VERSION ""

NS_ :

BS_:

BU_: XXX BCM CEM CVM DIM ECM FSM PSCM SAS SRS TCM

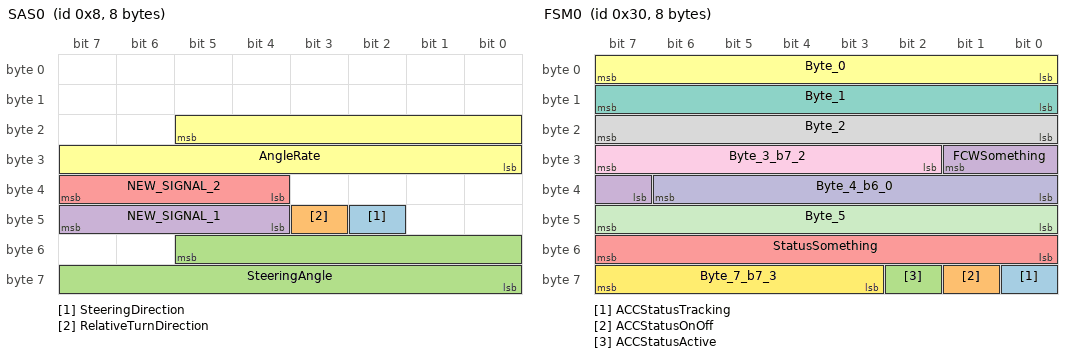
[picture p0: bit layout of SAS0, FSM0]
BO_ 8 SAS0: 8 SAS
 SG_ SteeringDirection : 42|1@0+ (1,0) [0|1] "" XXX
 SG_ RelativeTurnDirection : 43|1@0+ (1,0) [0|1] "" XXX
 SG_ SteeringAngle : 53|14@0+ (0.04395,0) [0|65535] "degrees" XXX
 SG_ NEW_SIGNAL_1 : 47|4@0+ (1,0) [0|15] "" XXX
 SG_ NEW_SIGNAL_2 : 39|4@0+ (1,0) [0|15] "" XXX
 SG_ AngleRate : 21|14@0+ (0.075,0) [0|1500] "deg/S" XXX

BO_ 16 CCButtons: 8 CEM
 SG_ byte0 : 7|8@0+ (1,0) [0|255] "" XXX
 SG_ byte1 : 15|8@0+ (1,0) [0|255] "" XXX
 SG_ byte2 : 23|8@0+ (1,0) [0|255] "" XXX
 SG_ byte3 : 31|8@0+ (1,0) [0|255] "" XXX
 SG_ byte4 : 39|8@0+ (1,0) [0|255] "" XXX
 SG_ byte6 : 55|5@0+ (1,0) [0|31] "" XXX
 SG_ B7b0 : 56|1@0+ (1,0) [0|1] "" XXX
 SG_ B7b1 : 57|1@0+ (1,0) [0|1] "" XXX
 SG_ B7b6 : 62|1@0+ (1,0) [0|1] "" XXX
 SG_ ACCOnOffBtn : 58|1@0+ (1,0) [0|1] "" XXX
 SG_ ACCSetBtn : 63|1@0+ (1,0) [0|1] "" XXX
 SG_ ACCStopBtn : 60|1@0+ (1,0) [0|1] "" XXX
 SG_ ACCResumeBtn : 61|1@0+ (1,0) [0|1] "" XXX
 SG_ ACCMinusBtn : 48|1@0+ (1,0) [0|1] "" XXX
 SG_ TimeGapIncreaseBtn : 49|1@0+ (1,0) [0|1] "" XXX
 SG_ TimeGapDecreaseBtn : 50|1@0+ (1,0) [0|1] "" XXX
 SG_ byte5 : 47|8@0+ (1,0) [0|255] "" XXX
 SG_ B7b3 : 59|1@0+ (1,0) [0|1] "" XXX

BO_ 48 FSM0: 8 FSM
 SG_ ACCStatusTracking : 56|1@0+ (1,0) [0|1] "" XXX
 SG_ ACCStatusOnOff : 57|1@0+ (1,0) [0|1] "" XXX
 SG_ ACCStatusActive : 58|1@0+ (1,0) [0|1] "" XXX
 SG_ FCWSomething : 25|3@0+ (1,0) [0|3] "" XXX
 SG_ StatusSomething : 55|8@0+ (1,0) [0|255] "" XXX
 SG_ Byte_0 : 7|8@0+ (1,0) [0|255] "" XXX
 SG_ Byte_1 : 15|8@0+ (1,0) [0|255] "" XXX
 SG_ Byte_2 : 23|8@0+ (1,0) [0|255] "" XXX
 SG_ Byte_3_b7_2 : 31|6@0+ (1,0) [0|63] "" XXX
 SG_ Byte_4_b6_0 : 38|7@0+ (1,0) [0|127] "" XXX
 SG_ Byte_5 : 47|8@0+ (1,0) [0|255] "" XXX
 SG_ Byte_7_b7_3 : 63|5@0+ (1,0) [0|31] "" XXX

BO_ 64 TCM0: 8 TCM
 SG_ RPMSomething : 42|11@0+ (1,0) [0|2047] "" XXX
 SG_ GearShifter : 46|2@0+ (1,0) [0|3] "" XXX

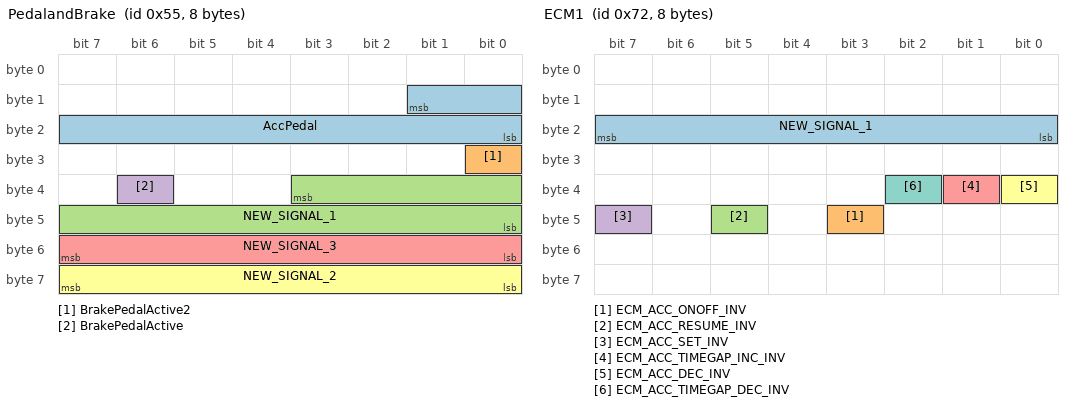
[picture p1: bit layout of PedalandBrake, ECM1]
BO_ 85 PedalandBrake: 8 ECM
 SG_ AccPedal : 9|10@0+ (0.1,0) [0|1023] "%" XXX
 SG_ BrakePedalActive2 : 24|1@0+ (1,0) [0|1] "" XXX
 SG_ NEW_SIGNAL_1 : 35|12@0+ (1,0) [0|4095] "" XXX
 SG_ BrakePedalActive : 38|1@0+ (1,0) [0|1] "" XXX
 SG_ NEW_SIGNAL_3 : 55|8@0+ (1,0) [0|255] "" XXX
 SG_ NEW_SIGNAL_2 : 63|8@0+ (1,0) [0|255] "" XXX

BO_ 101 EngineInfo: 8 XXX
 SG_ NEW_SIGNAL_1 : 17|10@0+ (1,-512) [0|1023] "" XXX
 SG_ EngineSpeed : 52|13@0+ (1,0) [0|1023] "" XXX

BO_ 112 NEW_MSG_4: 8 XXX
 SG_ NEW_SIGNAL_1 : 39|8@0+ (1,0) [0|255] "" XXX

BO_ 114 ECM1: 8 ECM
 SG_ NEW_SIGNAL_1 : 23|8@0+ (1,0) [0|255] "" XXX
 SG_ ECM_ACC_ONOFF_INV : 43|1@0+ (1,0) [0|1] "" XXX
 SG_ ECM_ACC_RESUME_INV : 45|1@0+ (1,0) [0|1] "" XXX
 SG_ ECM_ACC_SET_INV : 47|1@0+ (1,0) [0|1] "" XXX
 SG_ ECM_ACC_TIMEGAP_INC_INV : 33|1@0+ (1,0) [0|1] "" XXX
 SG_ ECM_ACC_DEC_INV : 32|1@0+ (1,0) [0|1] "" XXX
 SG_ ECM_ACC_TIMEGAP_DEC_INV : 34|1@0+ (1,0) [0|1] "" XXX

BO_ 117 ECM1_2: 8 ECM

BO_ 128 NEW_MSG_5: 8 XXX
 SG_ NEW_SIGNAL_2 : 26|11@0+ (1,0) [0|2047] "" XXX
 SG_ NEW_SIGNAL_1 : 52|13@0+ (1,0) [0|8191] "" XXX

BO_ 176 ECM2: 8 ECM
 SG_ NEW_SIGNAL_1 : 50|11@0+ (1,0) [0|2047] "" XXX
 SG_ NEW_SIGNAL_2 : 47|8@0+ (1,0) [0|63] "" XXX

BO_ 192 Gear: 8 XXX
 SG_ TransmissionGear : 36|3@0+ (1,1) [0|7] "" XXX

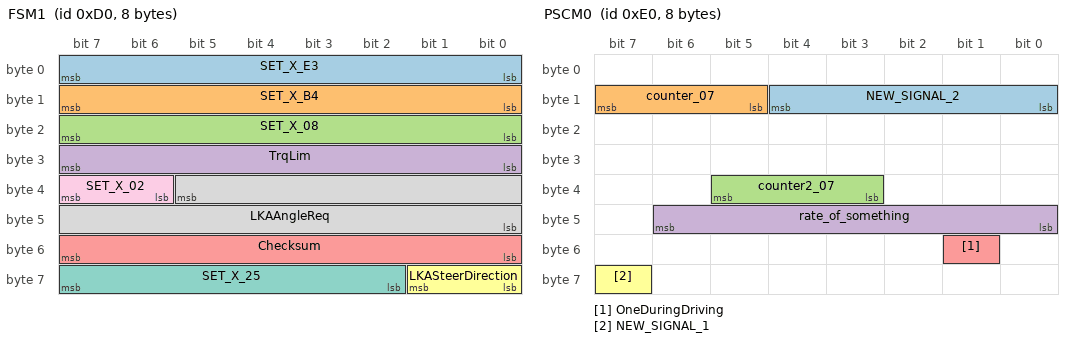
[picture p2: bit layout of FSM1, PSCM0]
BO_ 208 FSM1: 8 FSM
 SG_ SET_X_E3 : 7|8@0+ (1,0) [0|255] "" XXX
 SG_ SET_X_B4 : 15|8@0+ (1,0) [0|255] "" XXX
 SG_ SET_X_08 : 23|8@0+ (1,0) [0|255] "" XXX
 SG_ TrqLim : 31|8@0+ (1,-128) [0|255] "" XXX
 SG_ Checksum : 55|8@0+ (1,0) [0|255] "" XXX
 SG_ LKASteerDirection : 57|2@0+ (1,0) [0|2] "" XXX
 SG_ SET_X_25 : 63|6@0+ (1,0) [0|63] "" XXX
 SG_ LKAAngleReq : 37|14@0+ (0.04395,-360.0384) [-360.0384|359.99445] "degrees" XXX
 SG_ SET_X_02 : 39|2@0+ (1,0) [0|3] "" XXX

BO_ 224 PSCM0: 8 PSCM
 SG_ NEW_SIGNAL_2 : 12|5@0+ (1,0) [0|31] "" XXX
 SG_ counter_07 : 15|3@0+ (1,0) [0|7] "" XXX
 SG_ counter2_07 : 37|3@0+ (1,0) [0|16383] "" XXX
 SG_ rate_of_something : 46|7@0+ (1,0) [0|62] "" XXX
 SG_ OneDuringDriving : 49|1@0+ (1,0) [0|1] "" XXX
 SG_ NEW_SIGNAL_1 : 63|1@0+ (1,0) [0|1] "" XXX

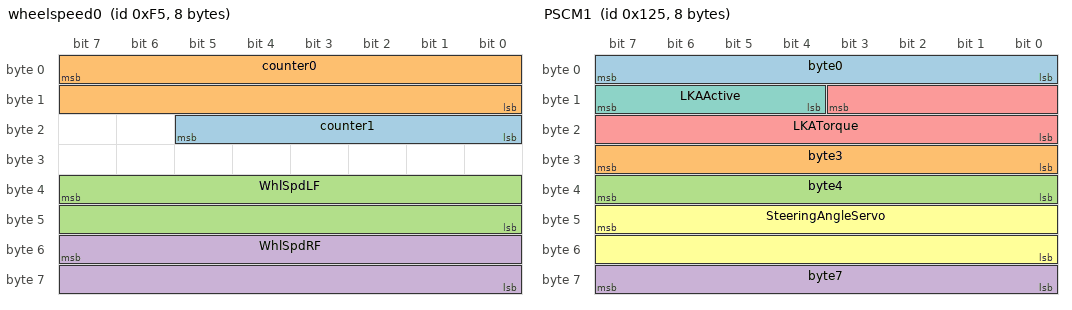
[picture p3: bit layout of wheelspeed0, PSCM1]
BO_ 245 wheelspeed0: 8 BCM
 SG_ counter1 : 21|6@0+ (1,0) [0|65535] "" XXX
 SG_ counter0 : 7|16@0+ (1,0) [0|65535] "" XXX
 SG_ WhlSpdLF : 39|16@0+ (1,0) [0|65535] "" XXX
 SG_ WhlSpdRF : 55|16@0+ (1,0) [0|65535] "" XXX

BO_ 272 SpeedSignal0: 8 XXX
 SG_ VehicleSpeedSignal : 55|16@0+ (0.01,0) [0|65535] "" XXX

BO_ 288 wheel_speed1: 8 BCM
 SG_ WhlSpdLR : 39|16@0+ (1,0) [0|65535] "" XXX
 SG_ WhlSpdRR : 55|16@0+ (1,0) [0|65535] "" XXX

BO_ 293 PSCM1: 8 PSCM
 SG_ byte0 : 7|8@0+ (1,0) [0|255] "" XXX
 SG_ byte3 : 31|8@0+ (1,0) [0|255] "" XXX
 SG_ byte4 : 39|8@0+ (1,0) [0|255] "" XXX
 SG_ byte7 : 63|8@0+ (1,0) [0|255] "" XXX
 SG_ LKATorque : 11|12@0+ (1,-2000) [0|4095] "" XXX
 SG_ SteeringAngleServo : 47|16@0+ (0.04395,-1440.1536) [0|65535] "deg" XXX
 SG_ LKAActive : 15|4@0+ (1,0) [0|15] "" XXX

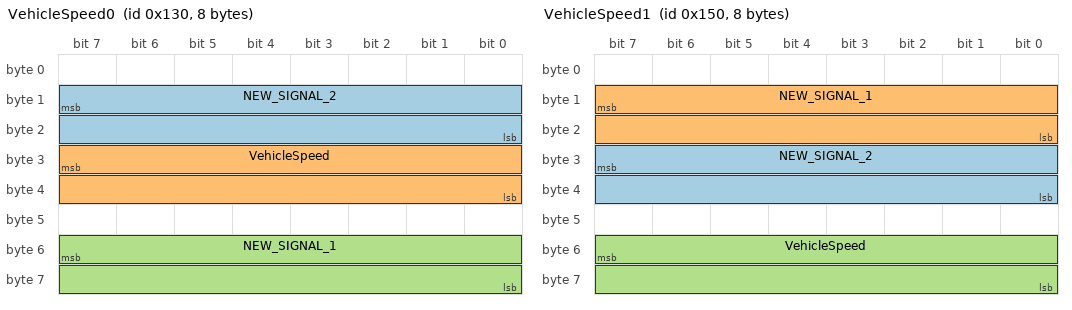
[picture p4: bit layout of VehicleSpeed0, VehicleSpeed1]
BO_ 304 VehicleSpeed0: 8 BCM
 SG_ NEW_SIGNAL_2 : 15|16@0+ (1,0) [0|65535] "" XXX
 SG_ VehicleSpeed : 31|16@0+ (0.01,0) [0|65535] "km/h" XXX
 SG_ NEW_SIGNAL_1 : 55|16@0+ (1,0) [0|65535] "" XXX

BO_ 325 ECM3: 8 ECM

BO_ 336 VehicleSpeed1: 8 BCM
 SG_ NEW_SIGNAL_2 : 31|16@0+ (1,0) [0|65535] "" XXX
 SG_ NEW_SIGNAL_1 : 15|16@0+ (1,0) [0|65535] "" XXX
 SG_ VehicleSpeed : 55|16@0+ (0.01,0) [0|65535] "" XXX

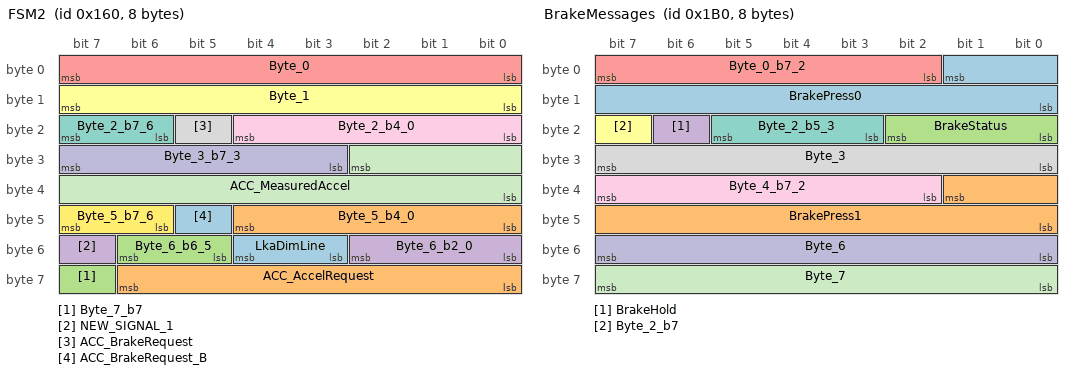
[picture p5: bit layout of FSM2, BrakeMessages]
BO_ 352 FSM2: 8 FSM
 SG_ LkaDimLine : 51|2@1+ (1,0) [0|127] "" XXX
 SG_ ACC_AccelRequest : 62|7@0+ (0.08,-5.12) [-5.12|5.04] "m/s^2" XXX
 SG_ Byte_7_b7 : 63|1@0+ (1,0) [0|1] "" XXX
 SG_ NEW_SIGNAL_1 : 55|1@0+ (1,0) [0|1] "" XXX
 SG_ Byte_0 : 7|8@0+ (1,0) [0|255] "" XXX
 SG_ Byte_1 : 15|8@0+ (1,0) [0|255] "" XXX
 SG_ Byte_2_b7_6 : 23|2@0+ (1,0) [0|3] "" XXX
 SG_ ACC_BrakeRequest : 21|1@0+ (1,0) [0|1] "" XXX
 SG_ Byte_2_b4_0 : 20|5@0+ (1,0) [0|31] "" XXX
 SG_ Byte_3_b7_3 : 31|5@0+ (1,0) [0|31] "" XXX
 SG_ ACC_MeasuredAccel : 26|11@0+ (0.00444,-4.573) [-4.573|4.516] "m/s^2" XXX
 SG_ Byte_5_b7_6 : 47|2@0+ (1,0) [0|3] "" XXX
 SG_ ACC_BrakeRequest_B : 45|1@0+ (1,0) [0|1] "" XXX
 SG_ Byte_5_b4_0 : 44|5@0+ (1,0) [0|31] "" XXX
 SG_ Byte_6_b6_5 : 54|2@0+ (1,0) [0|3] "" XXX
 SG_ Byte_6_b2_0 : 50|3@0+ (1,0) [0|7] "" XXX

BO_ 432 BrakeMessages: 8 BCM
 SG_ BrakePress0 : 1|10@0+ (1,0) [0|1023] "" XXX
 SG_ BrakePress1 : 33|10@0+ (1,0) [0|1023] "" XXX
 SG_ BrakeStatus : 18|3@0+ (1,0) [0|7] "" XXX
 SG_ BrakeHold : 22|1@0+ (1,0) [0|1] "" XXX
 SG_ Byte_0_b7_2 : 7|6@0+ (1,0) [0|63] "" XXX
 SG_ Byte_2_b7 : 23|1@0+ (1,0) [0|1] "" XXX
 SG_ Byte_2_b5_3 : 21|3@0+ (1,0) [0|7] "" XXX
 SG_ Byte_3 : 31|8@0+ (1,0) [0|255] "" XXX
 SG_ Byte_4_b7_2 : 39|6@0+ (1,0) [0|63] "" XXX
 SG_ Byte_6 : 55|8@0+ (1,0) [0|255] "" XXX
 SG_ Byte_7 : 63|8@0+ (1,0) [0|255] "" XXX

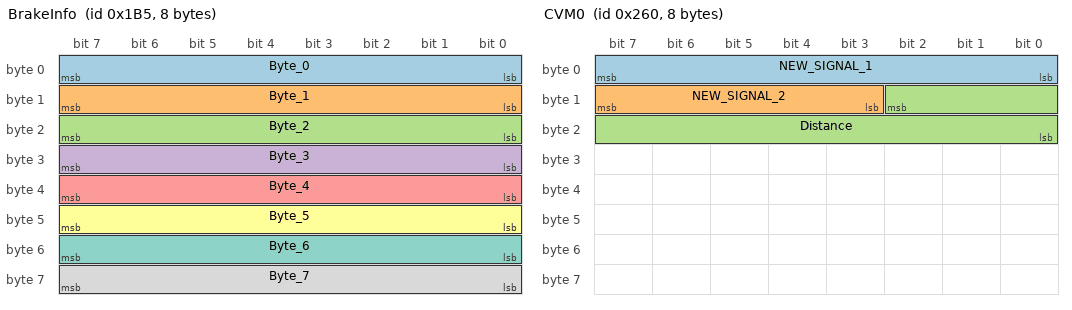
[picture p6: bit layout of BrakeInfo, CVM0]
BO_ 437 BrakeInfo: 8 XXX
 SG_ Byte_0 : 7|8@0+ (1,0) [0|255] "" XXX
 SG_ Byte_1 : 15|8@0+ (1,0) [0|255] "" XXX
 SG_ Byte_2 : 23|8@0+ (1,0) [0|255] "" XXX
 SG_ Byte_3 : 31|8@0+ (1,0) [0|255] "" XXX
 SG_ Byte_4 : 39|8@0+ (1,0) [0|255] "" XXX
 SG_ Byte_5 : 47|8@0+ (1,0) [0|255] "" XXX
 SG_ Byte_6 : 55|8@0+ (1,0) [0|255] "" XXX
 SG_ Byte_7 : 63|8@0+ (1,0) [0|255] "" XXX

BO_ 464 DIM0: 8 DIM

BO_ 480 BCM0: 8 BCM

BO_ 528 CEM0: 8 CEM
 SG_ LKA_State : 2|1@0+ (1,0) [0|1] "" XXX

BO_ 608 CVM0: 8 CVM
 SG_ NEW_SIGNAL_1 : 7|8@0+ (1,0) [0|255] "" XXX
 SG_ NEW_SIGNAL_2 : 15|5@0+ (1,0) [0|32] "" XXX
 SG_ Distance : 10|11@0+ (1,0) [0|2048] "" XXX

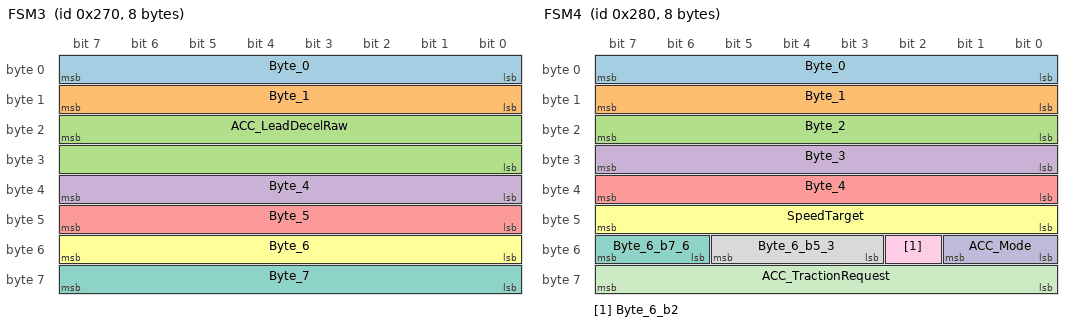
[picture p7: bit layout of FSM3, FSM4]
BO_ 624 FSM3: 8 FSM
 SG_ Byte_0 : 7|8@0+ (1,0) [0|255] "" XXX
 SG_ Byte_1 : 15|8@0+ (1,0) [0|255] "" XXX
 SG_ ACC_LeadDecelRaw : 23|16@0- (1,0) [-32768|32767] "" XXX
 SG_ Byte_4 : 39|8@0+ (1,0) [0|255] "" XXX
 SG_ Byte_5 : 47|8@0+ (1,0) [0|255] "" XXX
 SG_ Byte_6 : 55|8@0+ (1,0) [0|255] "" XXX
 SG_ Byte_7 : 63|8@0+ (1,0) [0|255] "" XXX

BO_ 640 FSM4: 8 FSM
 SG_ Byte_0 : 7|8@0+ (1,0) [0|255] "" XXX
 SG_ Byte_1 : 15|8@0+ (1,0) [0|255] "" XXX
 SG_ Byte_2 : 23|8@0+ (1,0) [0|255] "" XXX
 SG_ Byte_3 : 31|8@0+ (1,0) [0|255] "" XXX
 SG_ Byte_4 : 39|8@0+ (1,0) [0|255] "" XXX
 SG_ SpeedTarget : 47|8@0+ (1,0) [0|255] "" XXX
 SG_ Byte_6_b7_6 : 55|2@0+ (1,0) [0|3] "" XXX
 SG_ Byte_6_b5_3 : 53|3@0+ (1,0) [0|7] "" XXX
 SG_ Byte_6_b2 : 50|1@0+ (1,0) [0|1] "" XXX
 SG_ ACC_Mode : 49|2@0+ (1,0) [0|3] "" XXX
 SG_ ACC_TractionRequest : 63|8@0+ (1,0) [0|255] "" XXX

BO_ 648 SRS0: 8 SRS

BO_ 652 ECM4: 8 ECM

BO_ 656 ECM5: 8 ECM

BO_ 657 ECM6: 8 ECM

BO_ 681 MiscCarInfo: 8 CEM
 SG_ TurnSignal : 1|2@0+ (1,0) [0|3] "" XXX
 SG_ HighBeamOn : 52|1@0+ (1,0) [0|1] "" XXX

BO_ 693 ECM7: 8 ECM

BO_ 709 ACC: 8 ECM
 SG_ SpeedTargetACC : 0|9@0+ (0.5,0) [0|511] "" XXX
 SG_ ACC_PropulsionFeedback : 63|8@0+ (1,0) [0|255] "" XXX

BO_ 853 FSM5: 8 FSM
 SG_ TargetSpeedOdo : 23|8@0+ (1,0) [0|63] "kph" XXX
 SG_ SpeedSign : 36|5@0+ (5,0) [0|32] "" XXX
 SG_ TextUnderSign : 37|1@0+ (1,0) [0|1] "" XXX
 SG_ NEW_SIGNAL_6 : 39|3@0+ (1,0) [0|3] "" XXX
 SG_ NEW_SIGNAL_5 : 47|8@0+ (1,0) [0|255] "" XXX
 SG_ NEW_SIGNAL_3 : 31|8@0+ (1,0) [0|255] "" XXX
 SG_ LaneMarkingsOdo : 15|4@0+ (1,0) [0|7] "" XXX
 SG_ NEW_SIGNAL_2 : 11|4@0+ (1,0) [0|15] "" XXX
 SG_ NEW_SIGNAL_1 : 7|8@0+ (1,0) [0|255] "" XXX
 SG_ NEW_SIGNAL_4 : 55|16@0+ (1,0) [0|65535] "" XXX

BO_ 864 CEM1: 8 CEM
 SG_ ACC_DemandChangeFlag : 39|8@0+ (1,0) [0|255] "" XXX

BO_ 912 DIM1: 8 DIM

BO_ 968 SRS1: 8 SRS
 SG_ PassengerSeatBelt : 22|1@0+ (1,0) [0|1] "" XXX
 SG_ DriverSeatBelt : 19|1@0+ (1,0) [0|1] "" XXX

BO_ 1029 CEMBCM0: 8 CEM

BO_ 1344 NEW_MSG_1: 8 XXX
 SG_ NEW_SIGNAL_1 : 4|13@0+ (1,0) [0|8191] "" XXX

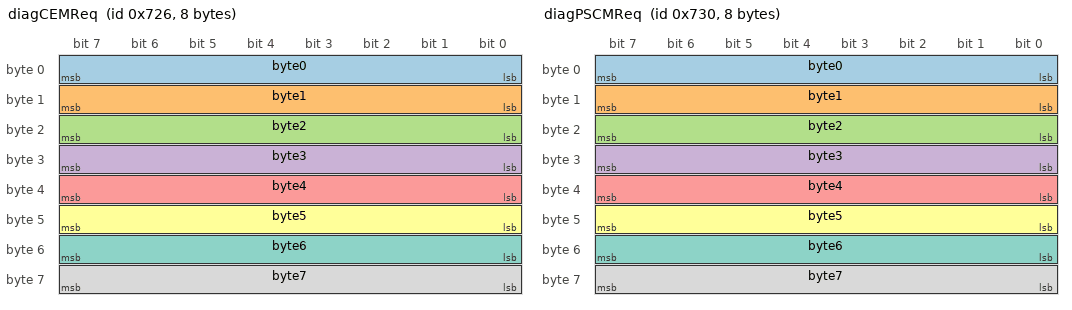
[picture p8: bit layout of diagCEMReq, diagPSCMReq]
BO_ 1830 diagCEMReq: 8 XXX
 SG_ byte0 : 7|8@0+ (1,0) [0|255] "" XXX
 SG_ byte1 : 15|8@0+ (1,0) [0|255] "" XXX
 SG_ byte2 : 23|8@0+ (1,0) [0|255] "" XXX
 SG_ byte3 : 31|8@0+ (1,0) [0|255] "" XXX
 SG_ byte4 : 39|8@0+ (1,0) [0|255] "" XXX
 SG_ byte5 : 47|8@0+ (1,0) [0|255] "" XXX
 SG_ byte6 : 55|8@0+ (1,0) [0|255] "" XXX
 SG_ byte7 : 63|8@0+ (1,0) [0|255] "" XXX

BO_ 1838 diagCEMResp: 8 XXX
 SG_ byte03 : 7|32@0+ (1,0) [0|4294967295] "" XXX
 SG_ byte47 : 39|32@0+ (1,0) [0|4294967295] "" XXX

BO_ 1840 diagPSCMReq: 8 XXX
 SG_ byte0 : 7|8@0+ (1,0) [0|255] "" XXX
 SG_ byte1 : 15|8@0+ (1,0) [0|255] "" XXX
 SG_ byte2 : 23|8@0+ (1,0) [0|255] "" XXX
 SG_ byte3 : 31|8@0+ (1,0) [0|255] "" XXX
 SG_ byte4 : 39|8@0+ (1,0) [0|255] "" XXX
 SG_ byte5 : 47|8@0+ (1,0) [0|255] "" XXX
 SG_ byte6 : 55|8@0+ (1,0) [0|255] "" XXX
 SG_ byte7 : 63|8@0+ (1,0) [0|255] "" XXX

BO_ 1848 diagPSCMResp: 8 XXX
 SG_ byte03 : 7|32@0+ (1,0) [0|4294967295] "" XXX
 SG_ byte47 : 39|32@0+ (1,0) [0|4294967295] "" XXX

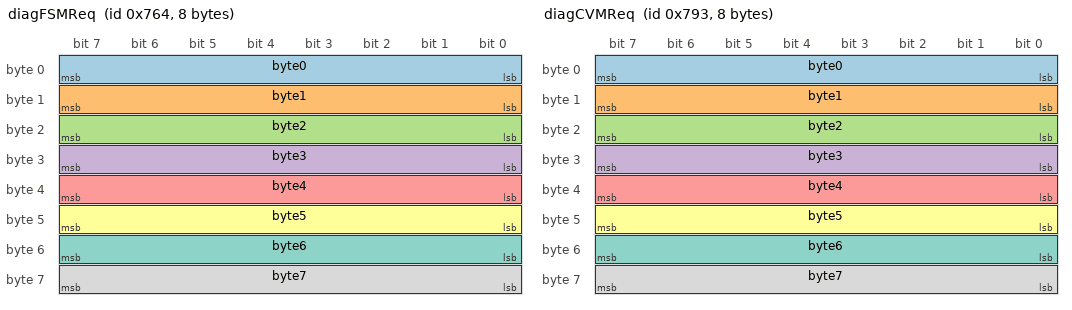
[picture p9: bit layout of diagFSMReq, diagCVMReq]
BO_ 1892 diagFSMReq: 8 XXX
 SG_ byte0 : 7|8@0+ (1,0) [0|255] "" XXX
 SG_ byte1 : 15|8@0+ (1,0) [0|255] "" XXX
 SG_ byte2 : 23|8@0+ (1,0) [0|255] "" XXX
 SG_ byte3 : 31|8@0+ (1,0) [0|255] "" XXX
 SG_ byte4 : 39|8@0+ (1,0) [0|255] "" XXX
 SG_ byte5 : 47|8@0+ (1,0) [0|255] "" XXX
 SG_ byte6 : 55|8@0+ (1,0) [0|255] "" XXX
 SG_ byte7 : 63|8@0+ (1,0) [0|255] "" XXX

BO_ 1900 diagFSMResp: 8 XXX
 SG_ byte03 : 7|32@0+ (1,0) [0|4294967295] "" XXX
 SG_ byte47 : 39|32@0+ (1,0) [0|4294967295] "" XXX

BO_ 1939 diagCVMReq: 8 XXX
 SG_ byte0 : 7|8@0+ (1,0) [0|255] "" XXX
 SG_ byte1 : 15|8@0+ (1,0) [0|255] "" XXX
 SG_ byte2 : 23|8@0+ (1,0) [0|255] "" XXX
 SG_ byte3 : 31|8@0+ (1,0) [0|255] "" XXX
 SG_ byte4 : 39|8@0+ (1,0) [0|255] "" XXX
 SG_ byte5 : 47|8@0+ (1,0) [0|255] "" XXX
 SG_ byte6 : 55|8@0+ (1,0) [0|255] "" XXX
 SG_ byte7 : 63|8@0+ (1,0) [0|255] "" XXX

BO_ 1947 diagCVMResp: 8 XXX
 SG_ byte03 : 7|32@0+ (1,0) [0|4294967295] "" XXX
 SG_ byte47 : 39|32@0+ (1,0) [0|4294967295] "" XXX

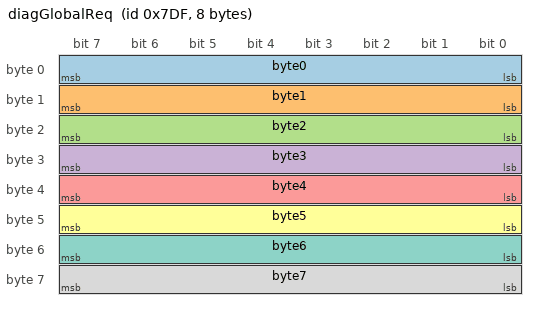
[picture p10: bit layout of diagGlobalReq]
BO_ 2015 diagGlobalReq: 8 XXX
 SG_ byte0 : 7|8@0+ (1,0) [0|255] "" XXX
 SG_ byte1 : 15|8@0+ (1,0) [0|255] "" XXX
 SG_ byte2 : 23|8@0+ (1,0) [0|255] "" XXX
 SG_ byte3 : 31|8@0+ (1,0) [0|255] "" XXX
 SG_ byte4 : 39|8@0+ (1,0) [0|255] "" XXX
 SG_ byte5 : 47|8@0+ (1,0) [0|255] "" XXX
 SG_ byte6 : 55|8@0+ (1,0) [0|255] "" XXX
 SG_ byte7 : 63|8@0+ (1,0) [0|255] "" XXX

CM_ SG_ 85 BrakePedalActive2 "Active during braking";
CM_ SG_ 85 NEW_SIGNAL_1 "Not yet figured out.";
CM_ SG_ 85 BrakePedalActive "Brake pedal pushed. Behaves like a pressure threshold (~75-100 on 0x1B0 BrakePress0), not a switch.";
CM_ SG_ 8 SteeringDirection "1=Right turn, 0=Left turn. Steering wheel pointing left or right from center (0 deg).";
CM_ SG_ 8 RelativeTurnDirection "1=Right turn, 0=Left turn. Steering wheel currently turning the way.";
CM_ SG_ 101 NEW_SIGNAL_1 "Rate of something?";
CM_ SG_ 192 TransmissionGear "0 = 1st gear, 1= 2nd gear...";
CM_ SG_ 681 TurnSignal "0 = Nothing, 1= Left, 3=Right";
CM_ SG_ 681 HighBeamOn "1=HighBeam On, 0=HighBeam Off";
CM_ SG_ 48 ACCStatusTracking "ACC Tracking vehicle, distance control.";
CM_ SG_ 48 ACCStatusOnOff "Turns one after pressing on/off button on steering wheel";
CM_ SG_ 48 ACCStatusActive "ACC Active. Byte 7 of 0x30 in the dashcam route: 0x8A = ACC standby, 0x8F = active tracking, 0x8E = active no tracking, 0x9F = active (bit 4 also set), 0x88 = off. In the 15 km/h route with openpilot running it stayed 0x88 throughout, unexplained.";
CM_ SG_ 48 FCWSomething "All bit set during fcw";
CM_ SG_ 48 StatusSomething "Some status changes when zeroing DTCs";
CM_ SG_ 208 TrqLim "Used in checksum calculation, Limit directional torque based on the number.";
CM_ SG_ 208 Checksum "Checksum calculated as a one-complement addition of LKAAngleRequest+LKADirection+Unkown, Zeros used to pad missing bits.";
CM_ SG_ 208 SET_X_02 "Bit 0 = Vibrate steering wheel., Bit 1 = Heartbeat";
CM_ SG_ 352 LkaDimLine "Not true, but follows lka steer direction.";
CM_ SG_ 352 NEW_SIGNAL_1 "Turned one. Got LKA service needed can this be the one?";
CM_ SG_ 640 ACC_Mode "Byte 6 bits 1-0 (bits 9-8 of the old 10-bit ACC_TractionRequest word). 0 = brake, 1 = coast, 2 = drive, same numbering as the V60 LongMode. Confirmed on 4 stock-ACC routes (7c7d3d5e5ff31d51 19/1a, 18eb05bab882ec44 1a/1b, ~1230 s ACC). The 0x160 ACC_AccelRequest value alone sorts the mode: below about -0.5 m/s2 brake, -0.5 to 0 coast, 0 and up drive, with hysteresis overlap.";
CM_ SG_ 640 ACC_TractionRequest "Byte 7, the traction value for ACC_Mode (was the low 8 bits of a 10-bit word with the mode on top). Unsigned in drive, signed in coast (0xEA = -22, engine drag), 0 in brake. Against the 0x160 ACC_AccelRequest (4 routes): drive = 86*a_req + 3 (r 0.93), coast = 54*a_req - 10 (r 0.73). Flat routes (grade within 2-3%) are tighter: drive about 92*a_req with ~0 offset (r 0.94-0.98), coast up to 93*a_req (r 0.85-0.97), close to the V60's 97/94. Hilly routes (5-6%) fit loosely (drive r 0.79-0.90, gain 63-78); adding a slope term changes nothing (at most 1 count per %), so the camera does not compensate grade in traction. Against measured aEgo: coast matches the V60 94*a - 9 (median error -0.02 to -0.04 m/s2), drive ~97*a + 35 (steady cruise needs 25-35 at any speed 20-120 km/h, because the camera requests about +0.3-0.5 m/s2 to hold speed). Medium-high confidence.";
CM_ SG_ 640 Byte_6_b7_6 "Always 3 (bits 15-14 of the word = 11), matching the V60 FSM4 brake word flags (0x8000 and 0x4000).";
CM_ SG_ 640 Byte_6_b5_3 "Bits 13-11 of the word, observed constant at 3 (011). Meaning unknown.";
CM_ SG_ 640 Byte_6_b2 "Bit 10 of the word. Clear whenever 0x270 byte 4 = 175 (11,700 of 11,708 frames in a manual drive; 10,540 of 10,544 in a highway ACC route), set otherwise. 175 is NOT ACC (seen with no ACC at all); most likely tied to openpilot being engaged, unproven. Explains the 0xD800 vs 0xDC00 floors seen in different routes.";
CM_ SG_ 640 SpeedTarget "SpeedTarget ACC (noisy bf starting acc Jumps from 0->252->0) Route 19: also behaves like a brake target, lower = more braking: median about 35 while ACC drives, about 0 while ACC brakes or holds, 252 with ACC off. Correlation with BrakePress0 during ACC braking only -0.34, so width and meaning are unconfirmed.";
CM_ BO_ 352 "0x160, camera to car (bus 2 -> relayed to bus 0), 50 Hz. Every 5th frame is a masked copy: the same frame with byte 0 & ~0x90, byte 2 & ~0xD5, byte 3 & ~0x40, byte 5 & ~0xD0 and byte 7 & ~0x80 (all 52,066 masked frames on 7 routes; the brake request bits survive). No counter or checksum: byte 6 bits 2-0 are a slow state (1/3/4/5), and the only full-range bytes are ACC_MeasuredAccel and ACC_AccelRequest. The signals cover all 64 bits, so a stock frame re-packs byte-identical.";
CM_ SG_ 352 ACC_BrakeRequest "UNCONFIRMED (medium-low). Set ~0.44 s before hydraulic pressure rises at both ACC braking events (586.3 s, 873.2 s). Not set on driver braking while moving. Also stays set at standstill with brake held. One 0.5 s false blip seen at 751 s with no braking. Also set in masked frames. Confirmed again in dashcam route (stock ACC stop 34-51 s) and 15 km/h route (decels at 110 s and 126 s): flag precedes hydraulic pressure and appears on ACC decel even without hydraulic braking. Route 19: 0.99 of samples while ACC brakes (0x1B0 byte 2 = 0xA5), 0.00 at ACC idle and in standstill hold. 5 routes: this is the HYDRAULIC brake request. In brake mode it agrees with BrakePress0 rising in 84-100% of frames, and pressure only rises with it set (median rise 28-40 with, 0 without). Never set outside 0x280 ACC_Mode = brake or with ACC off. Brake mode without it is engine braking only (two highway routes never set it). High confidence.";
CM_ SG_ 352 ACC_BrakeRequest_B "UNCONFIRMED. Same behaviour as ACC_BrakeRequest. Always set when ACC_BrakeRequest is set, and also sometimes alone (2270 frames). Route 19: it is the only one of the two set (1.00 of samples) during an ACC standstill hold, and 0.99 while ACC brakes.";
CM_ SG_ 352 ACC_AccelRequest "Byte 7 bits 6-0 (was NEW_SIGNAL_2 56|7@1+, same bits). The ACC acceleration request: (raw - 64) * ~0.08 m/s2, zero at 64. Braking side (5 routes incl. 00000008): 0.073-0.077 per count for firm requests, pooled fit 0.083; on flat routes 0.08 gives 0x280 traction gains of 90-94, matching the V60's 97/94. Leads measured aEgo by 0.2-0.4 s, sits on fixed values (raw 191/197 with bit 7) with ACC off, keeps falling through brake mode where traction is 0, and drive traction follows it at r 0.93. Looks like a 7-bit form of the V60 FSM3 ACC_AccelerationRequest (8-bit, 0.04). 4 stock-ACC routes, hardest request seen about -2 m/s2. Medium-high confidence.";
CM_ SG_ 352 Byte_7_b7 "Byte 7 bit 7. Always 1 in normal frames, 0 in the masked copies; likely a validity qualifier for ACC_AccelRequest.";
CM_ SG_ 352 ACC_MeasuredAccel "Byte 3 bits 2-0 + byte 4 (11 bits). MEASURED longitudinal acceleration, NOT a command: (raw - 1030) / ~225 m/s2 (fits 217-237 counts per m/s2 on 4 routes). Lags aEgo by 0.1-0.2 s and tracks it with ACC off too (r 0.87-0.95). This is what made the old Byte_4 sweep and the Byte_3 84 -> 82 drift during ACC braking (the high bits).";
CM_ SG_ 352 Byte_3_b7_3 "Byte 3 bits 7-3. Bit 6 is cleared in the masked copies (0x55 -> 0x15).";
CM_ SG_ 352 Byte_6_b2_0 "Byte 6 bits 2-0: 1, 3, 4 or 5, changing rarely (state, not a counter). Meaning unknown.";
CM_ SG_ 352 Byte_2_b4_0 "Byte 2 is 213 idle, 245 once ACC braking starts (only bit 5 differs). Replaces old NEW_SIGNAL_3 (7|24).";
CM_ SG_ 624 Byte_4 "Reads 0x87 or 0x00 with stock ACC engaged, so it is NOT the ACC engaged state. 0xAF (175) appears with no ACC at all (e.g. 4 stretches in a 2238 s manual drive) and begins before ACC is switched on, then continues after it ends; most likely tied to openpilot being engaged, unproven. Other values seen: 0x28 (40), 0x9F, 0xA7. Bit 10 of the 0x280 word (Byte_6_b2) is clear exactly when this reads 175.";
CM_ SG_ 528 LKA_State "0x210 byte 0 bit 2, 40 Hz, bus 0. Confirmed working as intended on the volvo_redlight branch. Seen in logs: on for the whole of a 1335 s manual drive and a highway route, never on in the 15 km/h set-speed route (likely LKA switched off for that drive). Follows the LKA enabled setting, not activity.";
CM_ SG_ 624 ACC_LeadDecelRaw "Signed 16-bit, -1 idle (about -230 steady with a lead in some logs). Goes strongly negative (to -3300 and lower) when a lead car ahead is braking, and stayed -1 during ACC own set-speed decels (-1.8 m/s2), so it is a lead-related decel demand, NOT the ACC decel request. Never positive. Low confidence. Route 19 (ACC active, gas off): correlates with measured acceleration, r = 0.67 at 0.3 s lag (the high byte carries it, adding the low byte changes nothing). Median -2539 while ACC brakes versus -236 at idle. Bytes 2 and 3 are one 16-bit value, not separate decel and traction fields. 4 routes: not -1 in 43-72% of moving ACC-off samples, ramps down about 1 s before ACC brakes and its peak does not match the braking achieved, so not an ACC command.";
CM_ SG_ 624 Byte_0 "Always 0";
CM_ SG_ 624 Byte_1 "Always 0";
CM_ SG_ 624 Byte_5 "0 or 2; 2 seen when throttle is on";
CM_ SG_ 624 Byte_6 "Always 0";
CM_ SG_ 624 Byte_7 "Always 0";
CM_ SG_ 640 Byte_0 "0x40, bit 3 sometimes set";
CM_ SG_ 864 ACC_DemandChangeFlag "10 Hz. Idle 164 (163 in manual). Under ACC it spikes high (~244-254) as ACC begins re-accelerating and low (0-21) when it begins decelerating. Event marker, not a request value. Medium confidence.";
CM_ SG_ 853 TargetSpeedOdo "Probably target speed odo";
CM_ SG_ 853 LaneMarkingsOdo "Bit 3=Left lane, Bit 2=Right lane, Bit 1=LKA on?, Bit 0=?";
CM_ SG_ 709 SpeedTargetACC "SpeedTargetACC";
CM_ SG_ 709 ACC_PropulsionFeedback "0x2C5 byte 7, ECM to camera (bus 0, echoed on bus 130), 16.7 Hz. Follows accelerator pedal (r~0.8). Pedal at zero: ~0 in manual driving, ~21 under ACC (ACC torque). Reads 0 during braking, ~25 at cruise, 160+ at +1.5 m/s2 (fit ~70*a+25). ECM output / feedback, NOT a request. Medium-low confidence.";
CM_ SG_ 224 rate_of_something "Seems to be some kind of torque rather than rate.";
CM_ SG_ 224 OneDuringDriving "Set to 1 when vehicle is rolling.";
CM_ SG_ 293 byte7 "Bit0=0 when gearshift in park, else 1";
CM_ SG_ 293 LKAActive "Bit0=0 when gear in park otherwise =1, Bit1=1 when LKA Active, 0 when not active. Bit2=? Bit3=?";
CM_ SG_ 16 ACCOnOffBtn "Cruise control on/off button pressed";
CM_ SG_ 16 ACCSetBtn "Acc Set button (+) pressed";
CM_ SG_ 16 ACCStopBtn "ACC Stop button pressed";
CM_ SG_ 16 ACCResumeBtn "ACC Resume button pressed";
CM_ SG_ 16 ACCMinusBtn "ACC Minus (-) button pressed";
CM_ SG_ 16 TimeGapIncreaseBtn "Increase the time gap on ACC";
CM_ SG_ 16 TimeGapDecreaseBtn "Decrease the time gap on ACC";
CM_ SG_ 245 counter0 "Speed based counter";
CM_ SG_ 245 WhlSpdLF "Wheel speed left front";
CM_ SG_ 245 WhlSpdRF "Wheel speed right front";
CM_ SG_ 288 WhlSpdLR "Wheel speed left rear";
CM_ SG_ 288 WhlSpdRR "Wheel speed right rear";
CM_ SG_ 64 RPMSomething "TransmissionOutput?";
CM_ SG_ 64 GearShifter "P=0, R=1, N=2, D=3";
CM_ SG_ 272 VehicleSpeedSignal "km/h";
CM_ SG_ 432 BrakeHold "Byte 2 bit 6. Set (0xE0/0xE1) while stock ACC holds the car at standstill.";
CM_ SG_ 432 BrakePress0 "Brake pressure. (byte0&3)<<8 | byte1. Rises under ACC braking with pedal flag off (peak ~108 at red-light event). Confirmed.";
CM_ SG_ 432 BrakePress1 "Brake pressure, second copy. (byte4&3)<<8 | byte5.";
CM_ SG_ 432 BrakeStatus "5 during ACC braking, 1 at standstill (observed). Other values not seen.";
CM_ BO_ 437 "0x1B5. Brake related, 10 ms, identical on bus 0 and bus 2 (camera sees it). Idle 2F FF C0 00 00 00 00 F8. Original Counter0-3 guesses (one per wheel?) not placed: bit layout unverified.";
CM_ SG_ 114 NEW_SIGNAL_1 "Jumped from 0 -> 120 during start. Makes triangle from time to time";
CM_ SG_ 608 NEW_SIGNAL_1 "Status?";
CM_ SG_ 608 NEW_SIGNAL_2 "Classification of object?";
CM_ SG_ 608 Distance "Distance to object in front. 1908 = no lead.";
CM_ SG_ 968 PassengerSeatBelt "1 = Seatbelt latched";
CM_ SG_ 968 DriverSeatBelt "1=Seatbelt latched";
CM_ BO_ 693 "0x2B5 ECM7. Brake-feedback candidate. Byte 2 is 0xF2 while stock ACC is braking (1.00 of samples on 3 routes), 0xB2 (0x9E parked/ACC off) otherwise incl. driver braking and coasting (<=0.001 false with ACC off). NOT sufficient: with ACC active and brake state idle it is also 0xF2 for 13-37% of samples (e.g. mild ACC slowdown at ~46 km/h, mostly >3 s from any 0xA5), so treat as necessary-not-sufficient. Edge leads the 0x1B0 byte 2 == 0xA5 edge by 90-460 ms. Also seen on bus 2 (camera). Observational only; nothing sent. The V60 ECM->FSM brake-feedback check suggests the camera compares such bytes with its own request. 0x2C3 (undefined here) byte 1 is 0x5C during ACC braking vs 0x54 otherwise, lag +100-200 ms, same pattern.";
CM_ BO_ 325 "0x145 ECM3. Byte 0 is the ACC standby-at-a-stop flag (observational): 0xA1 normally, 0xB9 from about 2.4-3.1 s into a standstill hold until the driver restarts it (wheel Resume, or the accelerator), then back to 0xA1 about 0.08 s after a successful Resume. Seen on 7 holds of 5.6-20.8 s on 4 routes, never during holds of 2.3 s or less (ACC resumes those by itself). Fits Volvo's documented ~3 s rule for Queue Assist. Not decoded further; byte 0 only.";
CM_ BO_ 480 "0x1E0 BCM0. Brake-feedback candidate. Byte 1 is 0x16 during ACC braking (0.92-0.94) vs 0x17 otherwise (<=0.002 false) on 3 routes. Lags the 0x1B0 A5 edge by 80-180 ms. Observational only.";
CM_ BO_ 176 "0xB0 ECM2. Byte 6 is 0xA3 during ACC braking (0.92-0.97) but also appears in ACC-active non-braking periods (0.35), so it is a state, not a clean brake confirmation. Leads the A5 edge by >1 s.";
CM_ BO_ 304 "0x130. Byte 6 tracks measured deceleration (r=0.91 driver braking, r=0.67 ACC braking) whatever causes it, so likely a continuous brake level or pressure value rather than an ACC flag. Observational only.";
VAL_ 64 GearShifter 0 "P" 1 "R" 2 "N" 3 "D" ;
VAL_ 432 BrakeStatus 1 "Standstill" 5 "ACC braking" ;
VAL_ 640 ACC_Mode 0 "Brake" 1 "Coast" 2 "Drive" ;%
